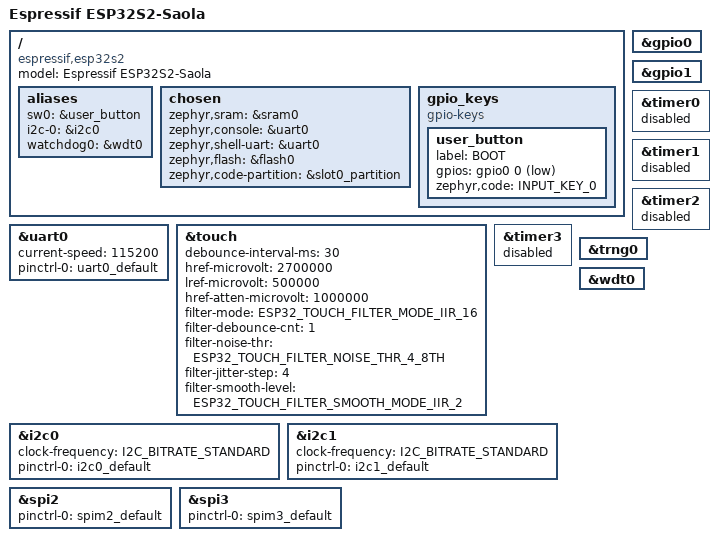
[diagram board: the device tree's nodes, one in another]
/*
 * Copyright (c) 2021 Espressif Systems (Shanghai) Co., Ltd.
 *
 * SPDX-License-Identifier: Apache-2.0
 */

/dts-v1/;

#include <espressif/esp32s2/esp32s2_wrover_n4r2.dtsi>
#include "esp32s2_saola-pinctrl.dtsi"
#include <zephyr/dt-bindings/input/input-event-codes.h>
#include <zephyr/dt-bindings/input/esp32-touch-sensor-input.h>
#include <espressif/partitions_0x1000_default.dtsi>

/ {
	model = "Espressif ESP32S2-Saola";
	compatible = "espressif,esp32s2";

	aliases {
		sw0 = &user_button;
		i2c-0 = &i2c0;
		watchdog0 = &wdt0;
	};

	chosen {
		zephyr,sram = &sram0;
		zephyr,console = &uart0;
		zephyr,shell-uart = &uart0;
		zephyr,flash = &flash0;
		zephyr,code-partition = &slot0_partition;
	};

	gpio_keys {
		compatible = "gpio-keys";
		user_button: user_button {
			label = "BOOT";
			gpios = <&gpio0 0 (GPIO_PULL_UP | GPIO_ACTIVE_LOW)>;
			zephyr,code = <INPUT_KEY_0>;
		};
	};
};

&uart0 {
	status = "okay";
	current-speed = <115200>;
	pinctrl-0 = <&uart0_default>;
	pinctrl-names = "default";
};

&gpio0 {
	status = "okay";
};

&gpio1 {
	status = "okay";
};

&touch {
	debounce-interval-ms = <30>;
	href-microvolt = <2700000>;
	lref-microvolt = <500000>;
	href-atten-microvolt = <1000000>;
	filter-mode = <ESP32_TOUCH_FILTER_MODE_IIR_16>;
	filter-debounce-cnt = <1>;
	filter-noise-thr = <ESP32_TOUCH_FILTER_NOISE_THR_4_8TH>;
	filter-jitter-step = <4>;
	filter-smooth-level = <ESP32_TOUCH_FILTER_SMOOTH_MODE_IIR_2>;
};

&timer0 {
	status = "disabled";
};

&timer1 {
	status = "disabled";
};

&timer2 {
	status = "disabled";
};

&timer3 {
	status = "disabled";
};

&i2c0 {
	status = "okay";
	clock-frequency = <I2C_BITRATE_STANDARD>;
	pinctrl-0 = <&i2c0_default>;
	pinctrl-names = "default";
};

&i2c1 {
	clock-frequency = <I2C_BITRATE_STANDARD>;
	pinctrl-0 = <&i2c1_default>;
	pinctrl-names = "default";
};

&trng0 {
	status = "okay";
};

&spi2 {
	#address-cells = <1>;
	#size-cells = <0>;
	status = "okay";
	pinctrl-0 = <&spim2_default>;
	pinctrl-names = "default";
};

&spi3 {
	#address-cells = <1>;
	#size-cells = <0>;
	status = "okay";
	pinctrl-0 = <&spim3_default>;
	pinctrl-names = "default";
};

&wdt0 {
	status = "okay";
};
